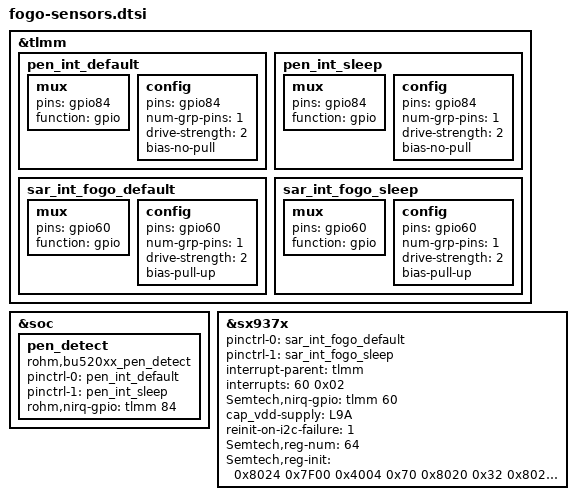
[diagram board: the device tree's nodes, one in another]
/*
 * Copyright (c) 2019, The Linux Foundation. All rights reserved.
 *
 * This program is free software; you can redistribute it and/or modify
 * it under the terms of the GNU General Public License version 2 and
 * only version 2 as published by the Free Software Foundation.
 *
 * This program is distributed in the hope that it will be useful,
 * but WITHOUT ANY WARRANTY; without even the implied warranty of
 * MERCHANTABILITY or FITNESS FOR A PARTICULAR PURPOSE.  See the
 * GNU General Public License for more details.
 */

&tlmm {
	pen_int_default: pen_int_default {
			mux {
				pins = "gpio84";
				function =  "gpio";
			};
			config {
				pins = "gpio84";
				num-grp-pins = <1>;
				drive-strength = <2>;
				bias-no-pull;
			};
	};

	pen_int_sleep: pen_int_sleep {
			mux {
				pins = "gpio84";
				function =  "gpio";
			};
			config {
				pins = "gpio84";
				num-grp-pins = <1>;
				drive-strength = <2>;
				bias-no-pull;
			};
	};

	sar_int_fogo_default: sar_int_fogo_default {
			mux {
				pins = "gpio60";
				function =  "gpio";
			};
			config {
				pins = "gpio60";
				num-grp-pins = <1>;
				drive-strength = <2>;
				bias-pull-up;
			};
	};

	sar_int_fogo_sleep: sar_int_fogo_sleep {
			mux {
				pins = "gpio60";
				function =  "gpio";
			};
			config {
				pins = "gpio60";
				num-grp-pins = <1>;
				drive-strength = <2>;
				bias-pull-up;
			};
	};
};

&soc {
	pen_detect{
		compatible = "rohm,bu520xx_pen_detect";
		pinctrl-names = "default","sleep";
		pinctrl-0 = <&pen_int_default>;
		pinctrl-1 = <&pen_int_sleep>;
		rohm,nirq-gpio=<&tlmm 84 0x02>;
	};
};

&sx937x {
		pinctrl-names = "default","sleep";
		pinctrl-0 = <&sar_int_fogo_default>;
		pinctrl-1 = <&sar_int_fogo_sleep>;
		interrupt-parent = <&tlmm>;
		interrupts = <60 0x02>;
		interrupt-names = "sx937x_irq";
		Semtech,nirq-gpio = <&tlmm 60 0x02>;
		cap_vdd-supply = <&L9A>;
		reinit-on-i2c-failure = <1>;
		Semtech,reg-num = <64>;
		Semtech,reg-init = <
			0x8024 0x7F00 	  /*PHEN, Disable all Phases*/
			0x4004 0x70       /*irq mask*/
			0x8020 0x32
			0x8028 0x85E
			0x8034 0x85E
			0x8040 0x85E
			0x804C 0x85E
			0x8058 0x85E
			0x8064 0x85E
			0x8070 0x85E
			0x807C 0x85E
			0x8030 0xFFF9FD
			0x803C 0xFFD9FF
			0x8048 0xFFF97F
			0x8054 0xBFF9FF
			0x8060 0xFEF9FF
			0x806C 0xFFF9EF
			0x8078 0xF7F9FF
			0x8084 0xFFFFFF
			0x8098 0x4E37
			0x80B8 0x4E37
			0x80D8 0x4E37
			0x80F8 0x4E37
			0x8118 0x4E37
			0x8138 0xFF
			0x8158 0xFF
			0x8178 0xC8
			0x80A0 0xE1
			0x80C0 0xE1
			0x80E0 0xE0
			0x8100 0xE2
			0x8120 0xE2
			0x8140 0x0
			0x8160 0x0
			0x8180 0x0
			0x8188 0x8000015
			0x818C 0x8000016
			0x8190 0x0
			0x8194 0x0
			0x8090 0x54C45000
			0x80B0 0x2AE27000
			0x80D0 0x54D45000
			0x80F0 0x2AE27000
			0x8110 0x2AE27000
			0x8130 0x2AD67000
			0x8150 0x2AD67000
			0x8170 0x2AD66000
			0x8088 0x300000
			0x80A8 0x300000
			0x80C8 0x300000
			0x80E8 0x300000
			0x8108 0x300000
			0x8128 0x6300000
			0x8148 0x6300000
			0x8168 0x300000
			0x808C 0x60200018
			0x80AC 0x60200018
			0x80CC 0x60200018
			0x80EC 0x60200018
			0x810C 0x60200018
			0x812C 0x60200018
			0x814C 0x60200018
			0x816C 0x60200018
			0x8024 0x7F7F
		>;
};

